# ISD9300_v3 register map
File version: 1.0
Registers are 32-bit, read-write, reset 0x0 unless marked. A register's access mark holds for its fields unless they carry their own. Offsets are from the block's base; [hi:lo] are bit positions.

## RTC — RTC Register Map
Base 0x40008000
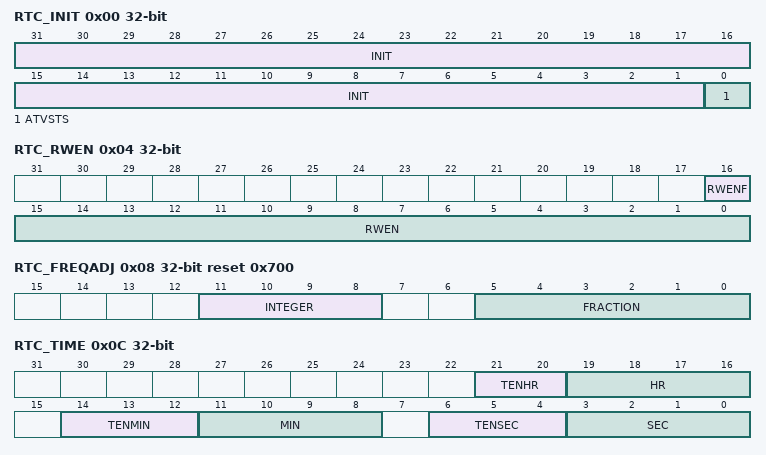
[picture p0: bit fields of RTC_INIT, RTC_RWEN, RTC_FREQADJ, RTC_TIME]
0x00 RTC_INIT — RTC Initialization Register
  [31:1] INIT — RTC Initialization. After a power-on reset (POR) RTC block should be initialized by writing 0xA5EB1357 to INIT. This will force a hardware reset then release all logic and counters.
  [0] ATVSTS ro — RTC Active Status (Read Only). 0: RTC is in reset state. 1: RTC is in normal active state.
0x04 RTC_RWEN — RTC Access Enable Register
  [16] RWENF ro — RTC Register Access Enable Flag (Read Only). This bit will be set after RWEN[15:0] register is set to 0xA965, it will clear automatically in 512 RTC clock cycles or RWEN[15:0] ! aaa 0xA965. The effect of RTC_RWEN.RWENF on access to each register is given Table 572. Table 572 RTC_RWEN.RWENF Register Access Effect. Register : RWENF aaa 1 : RWENF aaa 0. RTC_INIT : R/W : R/W. RTC_FREQADJ : R/W : - RTC_TIME : R/W : R. RTC_CAL : R/W : R. RTC_CLKFMT : R/W : R/W. RTC_WEEKDAY : R/W : R. RTC_TALM : R/W : - RTC_CALM : R/W : - RTC_LEAPYEAR : R : R. RTC_INTEN : R/W : R/W. RTC_INTSTS : R/W : R/W. RTC_TICK : R/W : -
    0=RTC register read/write disable; 1=RTC register read/write enable
  [15:0] RWEN wo — RTC Register Access Enable Password (Write Only). 0xA965 aaa Enable RTC access. Others aaa Disable RTC access
0x08 RTC_FREQADJ reset 0x700 — RTC Frequency Compensation Register
  [11:8] INTEGER — Integer Part. Register should contain the value (INT(Factual) - 32761). Ex: Integer part of detected value aaa 32772, RTC_FREQADJ.INTEGER aaa 32772-32761 aaa 11 (1011b). The range between 32761 and 32776
  [5:0] FRACTION — Fractional Part. Formula aaa (fraction part of detected value) x 60. Refer to 5.8.4.4 for the examples.
0x0C RTC_TIME — Time Load Register
  [21:20] TENHR — 10 Hour Time Digit (0~3)
  [19:16] HR — 1 Hour Time Digit (0~9)
  [14:12] TENMIN — 10 Min Time Digit (0~5)
  [11:8] MIN — 1 Min Time Digit (0~9)
  [6:4] TENSEC — 10 Sec Time Digit (0~5)
  [3:0] SEC — 1 Sec Time Digit (0~9)
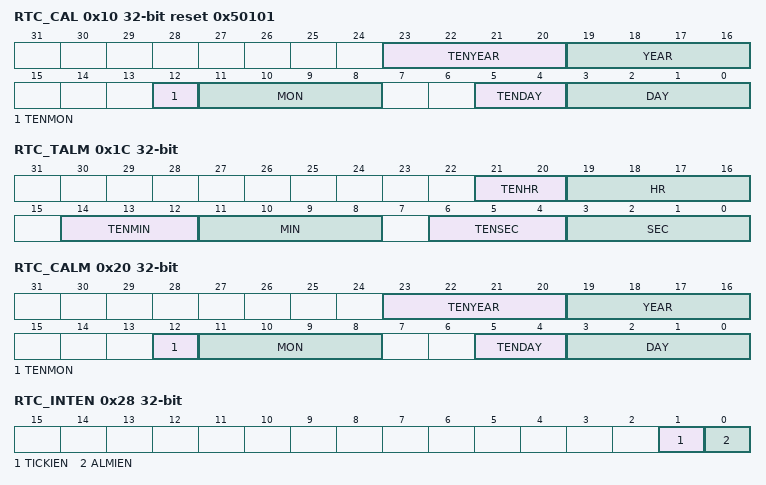
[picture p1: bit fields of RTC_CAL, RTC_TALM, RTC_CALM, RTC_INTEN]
0x10 RTC_CAL reset 0x50101 — Calendar Load Register
  [23:20] TENYEAR — 10-Year Calendar Digit (0~9)
  [19:16] YEAR — 1-Year Calendar Digit (0~9)
  [12] TENMON — 10-Month Calendar Digit (0~1)
  [11:8] MON — 1-Month Calendar Digit (0~9)
  [5:4] TENDAY — 10-Day Calendar Digit (0~3)
  [3:0] DAY — 1-Day Calendar Digit (0~9)
0x14 RTC_CLKFMT reset 0x1 — Time Scale Selection Register
  [0] _24HEN — 24-Hour / 12-Hour Mode Selection. Determines whether RTC_TIME and RTC_TALM are in 24-hour mode or 12-hour mode . The range of 24-hour time scale is between 0 and 23. 12-hour time scale: 01(AM01), 02(AM02), 03(AM03), 04(AM04), 05(AM05), 06(AM06). 07(AM07), 08(AM08), 09(AM09), 10(AM10), 11(AM11), 12(AM12). 21(PM01), 22(PM02), 23(PM03), 24(PM04), 25(PM05), 26(PM06). 27(PM07), 28(PM08), 29(PM09), 30(PM10), 31(PM11), 32(PM12)
    0=select 12-hour time scale with AM and PM indication; 1=select 24-hour time scale
0x18 RTC_WEEKDAY reset 0x6 — Day of the Week Register
  [2:0] WEEKDAY — Day Of The Week Register. 0 (Sunday), 1 (Monday), 2 (Tuesday), 3 (Wednesday). 4 (Thursday), 5 (Friday), 6 (Saturday)
0x1C RTC_TALM — Time Alarm Register
  [21:20] TENHR — 10 Hour Time Digit of Alarm Setting (0~3)2
  [19:16] HR — 1 Hour Time Digit of Alarm Setting (0~9)
  [14:12] TENMIN — 10 Min Time Digit of Alarm Setting (0~5)
  [11:8] MIN — 1 Min Time Digit of Alarm Setting (0~9)
  [6:4] TENSEC — 10 Sec Time Digit of Alarm Setting (0~5)
  [3:0] SEC — 1 Sec Time Digit of Alarm Setting (0~9)
0x20 RTC_CALM — Calendar Alarm Register
  [23:20] TENYEAR — 10-Year Calendar Digit of Alarm Setting (0~9)
  [19:16] YEAR — 1-Year Calendar Digit of Alarm Setting (0~9)
  [12] TENMON — 10-Month Calendar Digit of Alarm Setting (0~1)
  [11:8] MON — 1-Month Calendar Digit of Alarm Setting (0~9)
  [5:4] TENDAY — 10-Day Calendar Digit of Alarm Setting (0~3)
  [3:0] DAY — 1-Day Calendar Digit of Alarm Setting (0~9)
0x24 RTC_LEAPYEAR ro — Leap year Indicator Register
  [0] LEAPYEAR — Leap Year Indication Register (Read Only)
    0=Current year is not a leap year; 1=Current year is leap year
0x28 RTC_INTEN — RTC Interrupt Enable Register
  [1] TICKIEN — Time-Tick Interrupt And Wakeup-By-Tick Enable
    0=RTC Time-Tick Interrupt is disabled; 1=RTC Time-Tick Interrupt is enabled
  [0] ALMIEN — Alarm Interrupt Enable
    0=RTC Alarm Interrupt is disabled; 1=RTC Alarm Interrupt is enabled
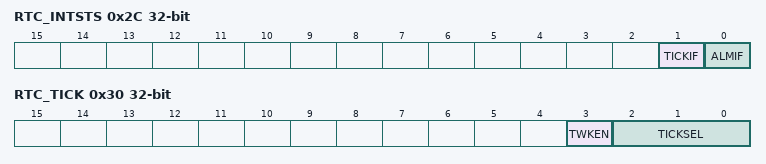
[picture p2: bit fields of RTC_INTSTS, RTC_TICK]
0x2C RTC_INTSTS — RTC Interrupt Indicator Register
  [1] TICKIF — RTC Time-Tick Interrupt Flag
    0=Indicates no Time-Tick Interrupt condition; 1=Indicates RTC Time-Tick Interrupt generated
  [0] ALMIF — RTC Alarm Interrupt Flag
    0=Indicates no Alarm Interrupt condition; 1=Indicates RTC Alarm Interrupt generated
0x30 RTC_TICK — RTC Time Tick Register
  [3] TWKEN — RTC Timer Wakeup CPU Function Enable Bit. If TWKE is set before CPU is in power-down mode, when a RTC Time-Tick or Alarm Match occurs, CPU will wake up.
    0=Disable Wakeup CPU function; 1=Enable the Wakeup function
  [2:0] TICKSEL — Time Tick Period Select. The RTC time tick period for Periodic Time-Tick Interrupt request. Time Tick (second) : 1 / (2^TTR). Note: This register can be read back after the RTC is active.
